# HC32F472 register map
File version: 1.0
CPU: CM4 r0p1, little endian, MPU, FPU, 4 interrupt priority bits
Registers are 32-bit, read-write, reset 0x0 unless marked. A register's access mark holds for its fields unless they carry their own. Offsets are from the block's base; [hi:lo] are bit positions; {n}, {i} and the like mark numbered series.

## KEYSCAN
Base 0x40050C00
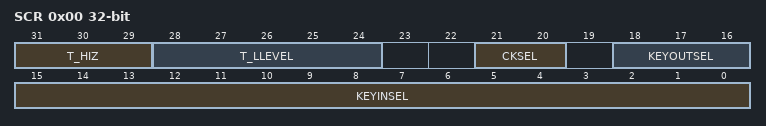
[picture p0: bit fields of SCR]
0x00 SCR
  [31:29] T_HIZ, [28:24] T_LLEVEL, [21:20] CKSEL, [18:16] KEYOUTSEL, [15:0] KEYINSEL
0x04 SER
  [0] SEN
0x08 SSR
  [2:0] INDEX

## MAU
Base 0x40055000
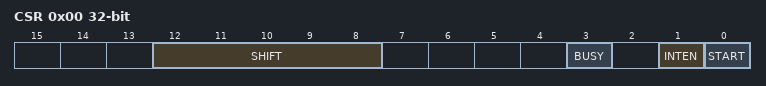
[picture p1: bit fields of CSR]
0x00 CSR
  [12:8] SHIFT, [3] BUSY, [1] INTEN, [0] START
0x04 DTR0
0x0C RTR0
  [16:0] SQRT_DOUT
0x10 DTR1
  [11:0] SIN_DIN
0x14 RTR1
  [15:0] SIN_DOUT

## MDIO
Base 0x40028400
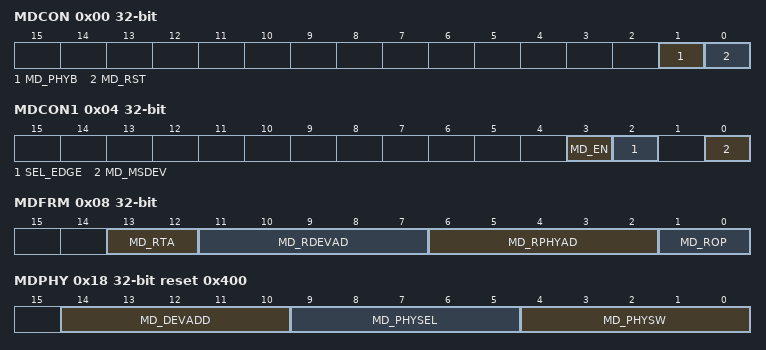
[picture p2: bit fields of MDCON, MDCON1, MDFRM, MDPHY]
0x00 MDCON
  [1] MD_PHYB, [0] MD_RST
0x04 MDCON1
  [3] MD_EN, [2] SEL_EDGE, [0] MD_MSDEV
0x08 MDFRM ro
  [13:12] MD_RTA, [11:7] MD_RDEVAD, [6:2] MD_RPHYAD, [1:0] MD_ROP
0x0C MDRXD ro
  [15:0] MD_RXD
0x10 MDADR ro
  [15:0] MD_ADR
0x14 MDTXD
  [15:0] MD_TXD
0x18 MDPHY reset 0x400
  [14:10] MD_DEVADD, [9:5] MD_PHYSEL, [4:0] MD_PHYSW
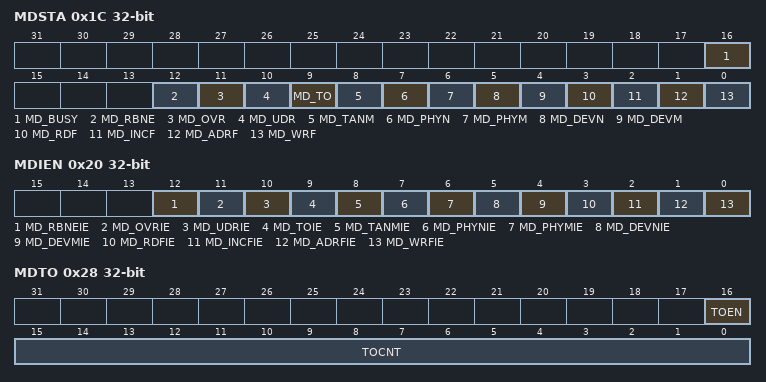
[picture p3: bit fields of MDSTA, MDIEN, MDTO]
0x1C MDSTA
  [16] MD_BUSY, [12] MD_RBNE, [11] MD_OVR, [10] MD_UDR, [9] MD_TO, [8] MD_TANM, [7] MD_PHYN, [6] MD_PHYM, [5] MD_DEVN, [4] MD_DEVM, [3] MD_RDF, [2] MD_INCF, [1] MD_ADRF, [0] MD_WRF
0x20 MDIEN
  [12] MD_RBNEIE, [11] MD_OVRIE, [10] MD_UDRIE, [9] MD_TOIE, [8] MD_TANMIE, [7] MD_PHYNIE, [6] MD_PHYMIE, [5] MD_DEVNIE, [4] MD_DEVMIE, [3] MD_RDFIE, [2] MD_INCFIE, [1] MD_ADRFIE, [0] MD_WRFIE
0x24 MDPIN ro
  [4:0] MD_PIN
0x28 MDTO
  [16] TOEN, [15:0] TOCNT

## MPU
Base 0x40050000
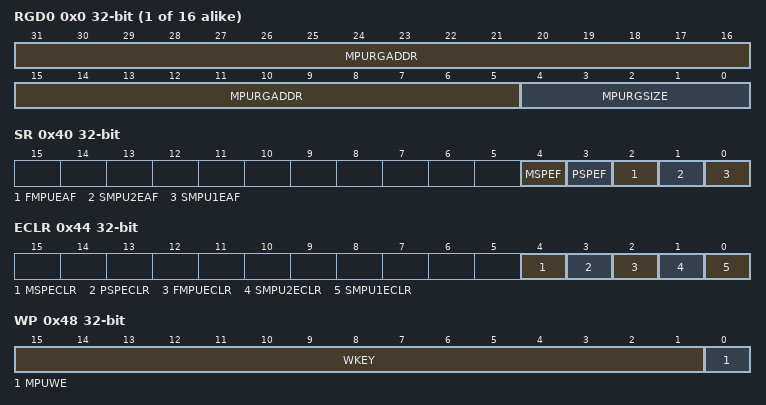
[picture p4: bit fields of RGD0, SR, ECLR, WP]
{0x0+4i} RGD{i} (i=0..15)
  [31:5] MPURGADDR, [4:0] MPURGSIZE
0x40 SR ro
  [4] MSPEF, [3] PSPEF, [2] FMPUEAF, [1] SMPU2EAF, [0] SMPU1EAF
0x44 ECLR wo
  [4] MSPECLR, [3] PSPECLR, [2] FMPUECLR, [1] SMPU2ECLR, [0] SMPU1ECLR
0x48 WP
  [15:1] WKEY, [0] MPUWE
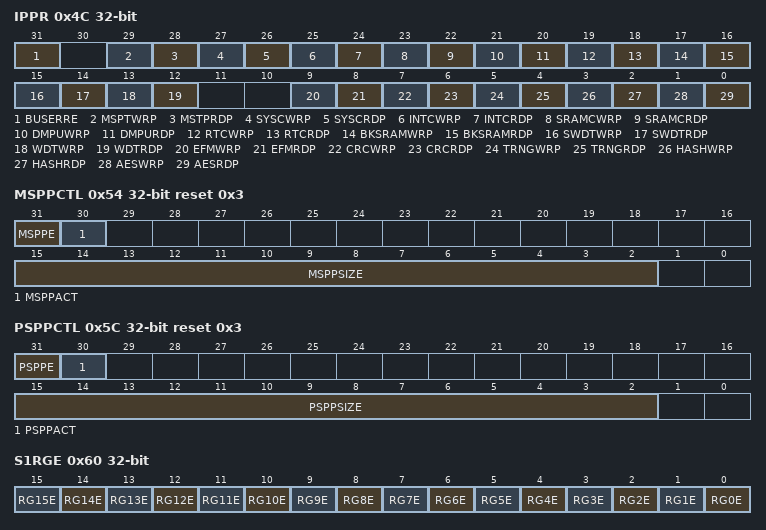
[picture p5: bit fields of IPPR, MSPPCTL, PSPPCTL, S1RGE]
0x4C IPPR
  [31] BUSERRE, [29] MSPTWRP, [28] MSTPRDP, [27] SYSCWRP, [26] SYSCRDP, [25] INTCWRP, [24] INTCRDP, [23] SRAMCWRP, [22] SRAMCRDP, [21] DMPUWRP, [20] DMPURDP, [19] RTCWRP, [18] RTCRDP, [17] BKSRAMWRP, [16] BKSRAMRDP, [15] SWDTWRP, [14] SWDTRDP, [13] WDTWRP, [12] WDTRDP, [9] EFMWRP, [8] EFMRDP, [7] CRCWRP, [6] CRCRDP, [5] TRNGWRP, [4] TRNGRDP, [3] HASHWRP, [2] HASHRDP, [1] AESWRP, [0] AESRDP
0x50 MSPPBA
  [31:2] MSPPBA
0x54 MSPPCTL reset 0x3
  [31] MSPPE, [30] MSPPACT, [15:2] MSPPSIZE
0x58 PSPPBA
  [31:2] PSPPBA
0x5C PSPPCTL reset 0x3
  [31] PSPPE, [30] PSPPACT, [15:2] PSPPSIZE
0x60 S1RGE
  [n] RG{n}E (n=0..15)
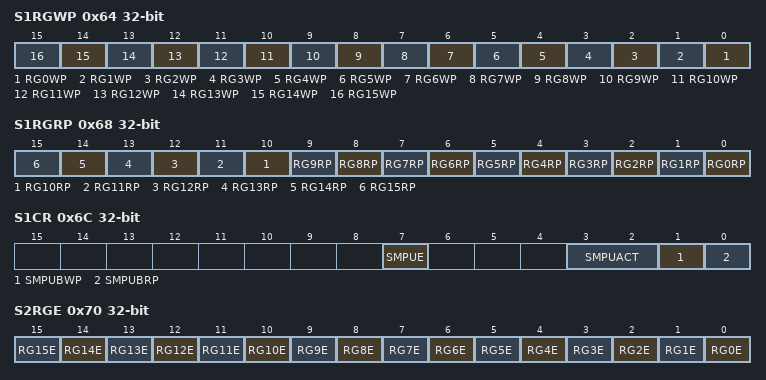
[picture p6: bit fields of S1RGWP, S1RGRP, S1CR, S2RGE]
0x64 S1RGWP
  [n] RG{n}WP (n=0..15)
0x68 S1RGRP
  [n] RG{n}RP (n=0..15)
0x6C S1CR
  [7] SMPUE, [3:2] SMPUACT, [1] SMPUBWP, [0] SMPUBRP
0x70 S2RGE
  [n] RG{n}E (n=0..15)
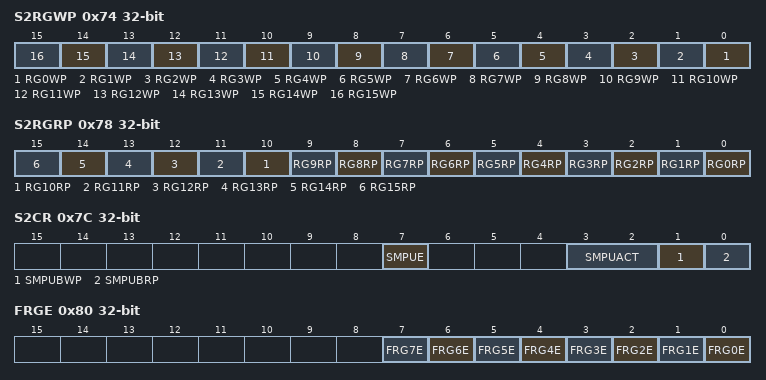
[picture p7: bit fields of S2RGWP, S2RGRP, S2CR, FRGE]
0x74 S2RGWP
  [n] RG{n}WP (n=0..15)
0x78 S2RGRP
  [n] RG{n}RP (n=0..15)
0x7C S2CR
  [7] SMPUE, [3:2] SMPUACT, [1] SMPUBWP, [0] SMPUBRP
0x80 FRGE
  [n] FRG{n}E (n=0..7)
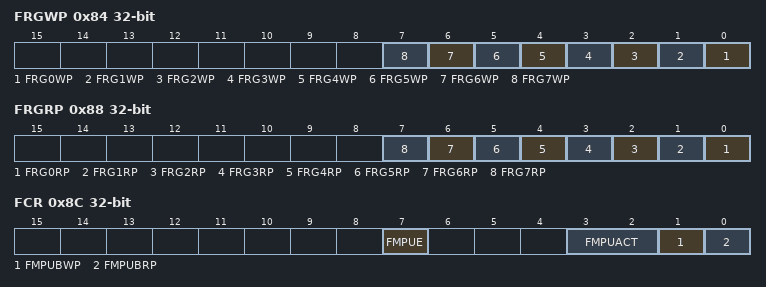
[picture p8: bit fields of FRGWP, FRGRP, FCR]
0x84 FRGWP
  [n] FRG{n}WP (n=0..7)
0x88 FRGRP
  [n] FRG{n}RP (n=0..7)
0x8C FCR
  [7] FMPUE, [3:2] FMPUACT, [1] FMPUBWP, [0] FMPUBRP

## OTS
Base 0x40010600
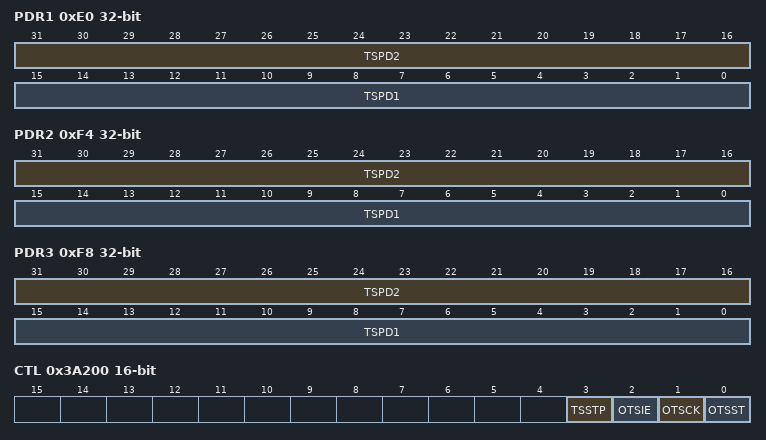
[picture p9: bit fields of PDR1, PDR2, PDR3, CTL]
0xE0 PDR1
  [31:16] TSPD2, [15:0] TSPD1
0xF4 PDR2
  [31:16] TSPD2, [15:0] TSPD1
0xF8 PDR3
  [31:16] TSPD2, [15:0] TSPD1
0x3A200 CTL 16-bit
  [3] TSSTP, [2] OTSIE, [1] OTSCK, [0] OTSST
0x3A202 DR1 16-bit
0x3A204 DR2 16-bit
0x3A206 ECR 16-bit

## PERIC
Base 0x40055400
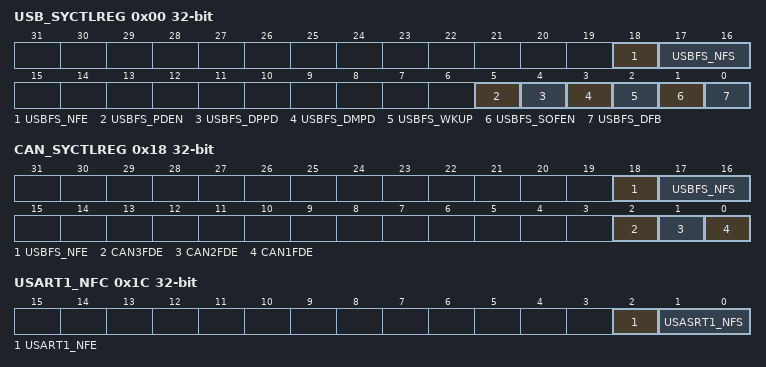
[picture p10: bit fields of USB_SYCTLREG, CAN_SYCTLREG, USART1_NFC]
0x00 USB_SYCTLREG
  [18] USBFS_NFE, [17:16] USBFS_NFS, [5] USBFS_PDEN, [4] USBFS_DPPD, [3] USBFS_DMPD, [2] USBFS_WKUP, [1] USBFS_SOFEN, [0] USBFS_DFB
0x0C SMC_ENAR
  [1] SMCEN
0x18 CAN_SYCTLREG
  [18] USBFS_NFE, [17:16] USBFS_NFS, [2] CAN3FDE, [1] CAN2FDE, [0] CAN1FDE
0x1C USART1_NFC
  [2] USART1_NFE, [1:0] USASRT1_NFS

## PLA
Base 0x4004FC00
0x00 GCTL
  [15:0] PLA_EN
0x0C STAT ro
  [15:0] PLA_OUT
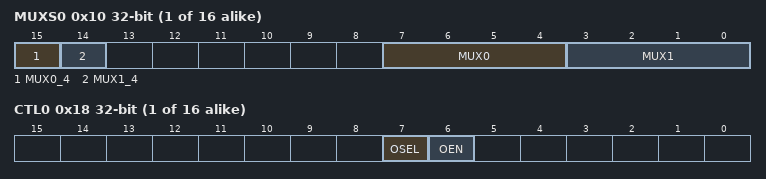
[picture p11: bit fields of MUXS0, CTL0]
{0x10+0xC*i} MUXS{i} (i=0..15)
  [15] MUX0_4, [14] MUX1_4, [7:4] MUX0, [3:0] MUX1
{0x14+0xC*i} LUTCTL{i} (i=0..15)
  [7:0] LUTCTL
{0x18+0xC*i} CTL{i} (i=0..15)
  [7] OSEL, [6] OEN

## PWC
Base 0x40048000; alternate view of CMU
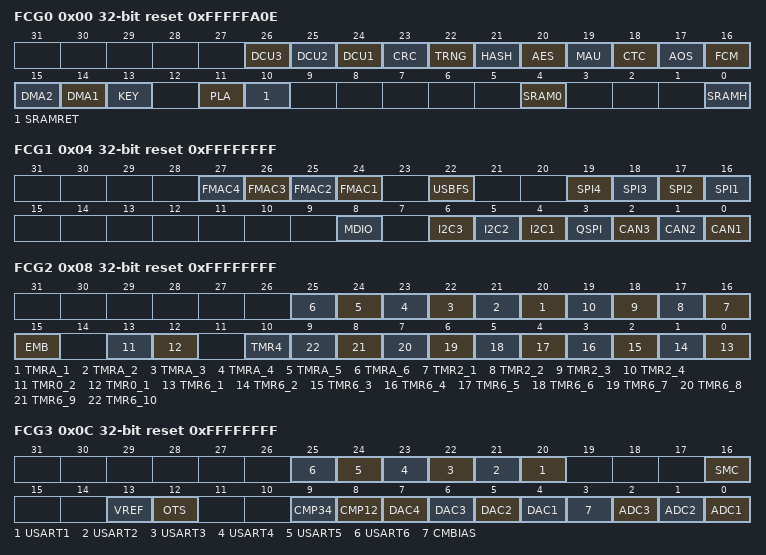
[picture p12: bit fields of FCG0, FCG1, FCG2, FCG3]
0x00 FCG0 reset 0xFFFFFA0E
  [26] DCU3, [25] DCU2, [24] DCU1, [23] CRC, [22] TRNG, [21] HASH, [20] AES, [19] MAU, [18] CTC, [17] AOS, [16] FCM, [15] DMA2, [14] DMA1, [13] KEY, [11] PLA, [10] SRAMRET, [4] SRAM0, [0] SRAMH
0x04 FCG1 reset 0xFFFFFFFF
  [n+23] FMAC{n} (n=1..4), [22] USBFS, [n+15] SPI{n} (n=1..4), [8] MDIO, [6] I2C3, [5] I2C2, [4] I2C1, [3] QSPI, [2] CAN3, [1] CAN2, [0] CAN1
0x08 FCG2 reset 0xFFFFFFFF
  [n+19] TMRA_{n} (n=1..6), [n+15] TMR2_{n} (n=1..4), [15] EMB, [13] TMR0_2, [12] TMR0_1, [10] TMR4, [n-1] TMR6_{n} (n=1..10)
0x0C FCG3 reset 0xFFFFFFFF
  [n+19] USART{n} (n=1..6), [16] SMC, [13] VREF, [12] OTS, [9] CMP34, [8] CMP12, [n+3] DAC{n} (n=1..4), [3] CMBIAS, [2] ADC3, [1] ADC2, [0] ADC1
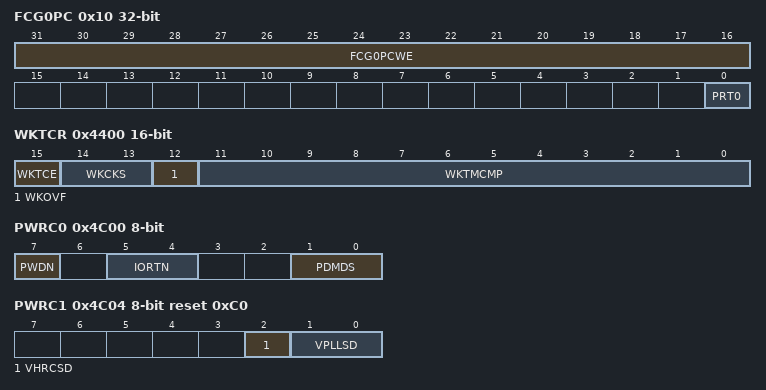
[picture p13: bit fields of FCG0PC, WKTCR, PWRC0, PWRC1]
0x10 FCG0PC
  [31:16] FCG0PCWE wo, [0] PRT0
0x4400 WKTCR 16-bit
  [15] WKTCE, [14:13] WKCKS, [12] WKOVF, [11:0] WKTMCMP
0x4C00 PWRC0 8-bit
  [7] PWDN, [5:4] IORTN, [1:0] PDMDS
0x4C04 PWRC1 8-bit reset 0xC0
  [2] VHRCSD, [1:0] VPLLSD
0x4C10 PWRC4 8-bit
  [7] ADBUFE
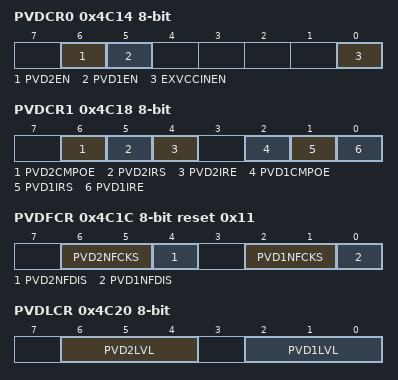
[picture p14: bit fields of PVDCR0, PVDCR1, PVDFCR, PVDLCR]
0x4C14 PVDCR0 8-bit
  [6] PVD2EN, [5] PVD1EN, [0] EXVCCINEN
0x4C18 PVDCR1 8-bit
  [6] PVD2CMPOE, [5] PVD2IRS, [4] PVD2IRE, [2] PVD1CMPOE, [1] PVD1IRS, [0] PVD1IRE
0x4C1C PVDFCR 8-bit reset 0x11
  [6:5] PVD2NFCKS, [4] PVD2NFDIS, [2:1] PVD1NFCKS, [0] PVD1NFDIS
0x4C20 PVDLCR 8-bit
  [6:4] PVD2LVL, [2:0] PVD1LVL
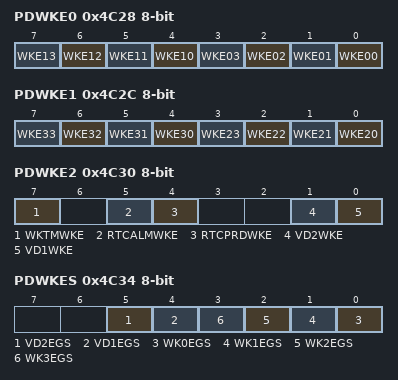
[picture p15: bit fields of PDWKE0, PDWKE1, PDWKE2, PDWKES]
0x4C28 PDWKE0 8-bit
  [n-6] WKE{n} (n=10..13), [n] WKE{n:02} (n=0..3)
0x4C2C PDWKE1 8-bit
  [n-26] WKE{n} (n=30..33), [n-20] WKE{n} (n=20..23)
0x4C30 PDWKE2 8-bit
  [7] WKTMWKE, [5] RTCALMWKE, [4] RTCPRDWKE, [1] VD2WKE, [0] VD1WKE
0x4C34 PDWKES 8-bit
  [5] VD2EGS, [4] VD1EGS, [n] WK{n}EGS (n=0..3)
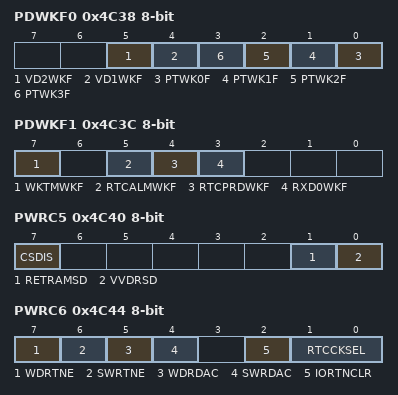
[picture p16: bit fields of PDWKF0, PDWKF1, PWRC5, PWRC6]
0x4C38 PDWKF0 8-bit
  [5] VD2WKF, [4] VD1WKF, [n] PTWK{n}F (n=0..3)
0x4C3C PDWKF1 8-bit
  [7] WKTMWKF, [5] RTCALMWKF, [4] RTCPRDWKF, [3] RXD0WKF
0x4C40 PWRC5 8-bit
  [7] CSDIS, [1] RETRAMSD, [0] VVDRSD
0x4C44 PWRC6 8-bit (reset mask 0xF5)
  [7] WDRTNE, [6] SWRTNE, [5] WDRDAC, [4] SWRDAC, [2] IORTNCLR, [1:0] RTCCKSEL
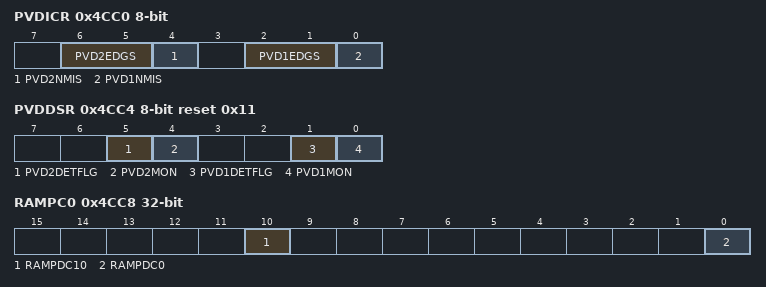
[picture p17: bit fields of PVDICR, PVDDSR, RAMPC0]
0x4CC0 PVDICR 8-bit
  [6:5] PVD2EDGS, [4] PVD2NMIS, [2:1] PVD1EDGS, [0] PVD1NMIS
0x4CC4 PVDDSR 8-bit reset 0x11
  [5] PVD2DETFLG, [4] PVD2MON, [1] PVD1DETFLG, [0] PVD1MON
0x4CC8 RAMPC0
  [10] RAMPDC10, [0] RAMPDC0
0x4CD0 PRAMLPC
  [n] PRAMPDC{n} (n=0..3)
0xC00C STPMCR 16-bit
  [15] STOP, [14] EXBUSOE, [1] CKSMRC, [0] FLNWT
0xC3FE FPRC 16-bit
  [15:8] FPRCWE, [n] FPRCB{n} (n=0..3)
